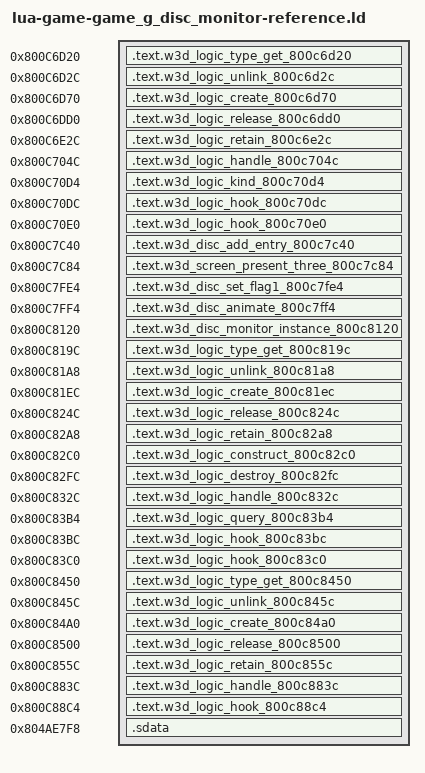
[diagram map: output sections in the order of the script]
/* Generated reference-only placements. All bodies are source-built. */
OUTPUT_FORMAT("elf32-powerpc")
OUTPUT_ARCH(powerpc)
ENTRY(w3d_logic_type_get_800c6d20)
_SDA_BASE_ = 0x804b2540;
_SDA2_BASE_ = 0x804c2540;
atexit = 0x802ed7e0;
w3d_actor_handle_8015fb34 = 0x8015fb34;
w3d_disc_monitor_8043e464 = 0x8043e464;
w3d_disc_monitor_destroy_800c6cf4 = 0x800c6cf4;
w3d_f32_80387a5c = 0x80387a5c;
w3d_heap_allocate_entry_a = 0x801fe1d8;
w3d_logic_base_destroy_801628ec = 0x801628ec;
w3d_logic_base_handle_8016293c = 0x8016293c;
w3d_logic_base_init_801628b0 = 0x801628b0;
w3d_logic_construct_800c6e44 = 0x800c6e44;
w3d_logic_construct_800c8574 = 0x800c8574;
w3d_logic_destroy_800c6f20 = 0x800c6f20;
w3d_logic_destroy_800c8630 = 0x800c8630;
w3d_logic_hook_800c8e90 = 0x800c8e90;
w3d_logic_type_80360ae0 = 0x80360ae0;
w3d_logic_type_80360b10 = 0x80360b10;
w3d_logic_type_80360b40 = 0x80360b40;
w3d_message_is_8015f620 = 0x8015f620;
w3d_owner_list_remove = 0x8020fd2c;
w3d_panel_set_frame_80173f88 = 0x80173f88;
w3d_state_register = 0x8020fd04;
w3d_time_now_801fe45c = 0x801fe45c;
w3d_vtable_8040fae8 = 0x8040fae8;
SECTIONS {
  .text.w3d_logic_type_get_800c6d20 0x800c6d20 : { *(.text.w3d_logic_type_get_800c6d20) }
  .text.w3d_logic_unlink_800c6d2c 0x800c6d2c : { *(.text.w3d_logic_unlink_800c6d2c) }
  .text.w3d_logic_create_800c6d70 0x800c6d70 : { *(.text.w3d_logic_create_800c6d70) }
  .text.w3d_logic_release_800c6dd0 0x800c6dd0 : { *(.text.w3d_logic_release_800c6dd0) }
  .text.w3d_logic_retain_800c6e2c 0x800c6e2c : { *(.text.w3d_logic_retain_800c6e2c) }
  .text.w3d_logic_handle_800c704c 0x800c704c : { *(.text.w3d_logic_handle_800c704c) }
  .text.w3d_logic_kind_800c70d4 0x800c70d4 : { *(.text.w3d_logic_kind_800c70d4) }
  .text.w3d_logic_hook_800c70dc 0x800c70dc : { *(.text.w3d_logic_hook_800c70dc) }
  .text.w3d_logic_hook_800c70e0 0x800c70e0 : { *(.text.w3d_logic_hook_800c70e0) }
  .text.w3d_disc_add_entry_800c7c40 0x800c7c40 : { *(.text.w3d_disc_add_entry_800c7c40) }
  .text.w3d_screen_present_three_800c7c84 0x800c7c84 : { *(.text.w3d_screen_present_three_800c7c84) }
  .text.w3d_disc_set_flag1_800c7fe4 0x800c7fe4 : { *(.text.w3d_disc_set_flag1_800c7fe4) }
  .text.w3d_disc_animate_800c7ff4 0x800c7ff4 : { *(.text.w3d_disc_animate_800c7ff4) }
  .text.w3d_disc_monitor_instance_800c8120 0x800c8120 : { *(.text.w3d_disc_monitor_instance_800c8120) }
  .text.w3d_logic_type_get_800c819c 0x800c819c : { *(.text.w3d_logic_type_get_800c819c) }
  .text.w3d_logic_unlink_800c81a8 0x800c81a8 : { *(.text.w3d_logic_unlink_800c81a8) }
  .text.w3d_logic_create_800c81ec 0x800c81ec : { *(.text.w3d_logic_create_800c81ec) }
  .text.w3d_logic_release_800c824c 0x800c824c : { *(.text.w3d_logic_release_800c824c) }
  .text.w3d_logic_retain_800c82a8 0x800c82a8 : { *(.text.w3d_logic_retain_800c82a8) }
  .text.w3d_logic_construct_800c82c0 0x800c82c0 : { *(.text.w3d_logic_construct_800c82c0) }
  .text.w3d_logic_destroy_800c82fc 0x800c82fc : { *(.text.w3d_logic_destroy_800c82fc) }
  .text.w3d_logic_handle_800c832c 0x800c832c : { *(.text.w3d_logic_handle_800c832c) }
  .text.w3d_logic_query_800c83b4 0x800c83b4 : { *(.text.w3d_logic_query_800c83b4) }
  .text.w3d_logic_hook_800c83bc 0x800c83bc : { *(.text.w3d_logic_hook_800c83bc) }
  .text.w3d_logic_hook_800c83c0 0x800c83c0 : { *(.text.w3d_logic_hook_800c83c0) }
  .text.w3d_logic_type_get_800c8450 0x800c8450 : { *(.text.w3d_logic_type_get_800c8450) }
  .text.w3d_logic_unlink_800c845c 0x800c845c : { *(.text.w3d_logic_unlink_800c845c) }
  .text.w3d_logic_create_800c84a0 0x800c84a0 : { *(.text.w3d_logic_create_800c84a0) }
  .text.w3d_logic_release_800c8500 0x800c8500 : { *(.text.w3d_logic_release_800c8500) }
  .text.w3d_logic_retain_800c855c 0x800c855c : { *(.text.w3d_logic_retain_800c855c) }
  .text.w3d_logic_handle_800c883c 0x800c883c : { *(.text.w3d_logic_handle_800c883c) }
  .text.w3d_logic_hook_800c88c4 0x800c88c4 : { *(.text.w3d_logic_hook_800c88c4) }
  .sdata 0x804ae7f8 (NOLOAD) : {
    . = 0x0; w3d_disc_monitor_ready_804ae7f8 = .;
    . = 0x14; w3d_message_804ae80c = .;
    . = 0x2f90; w3d_game_804b1788 = .;
    . += 1; }
  /DISCARD/ : { *(.text*) *(.rodata*) *(.data*) *(.bss*) *(.sdata*) *(.sbss*) *(.comment) }
}
